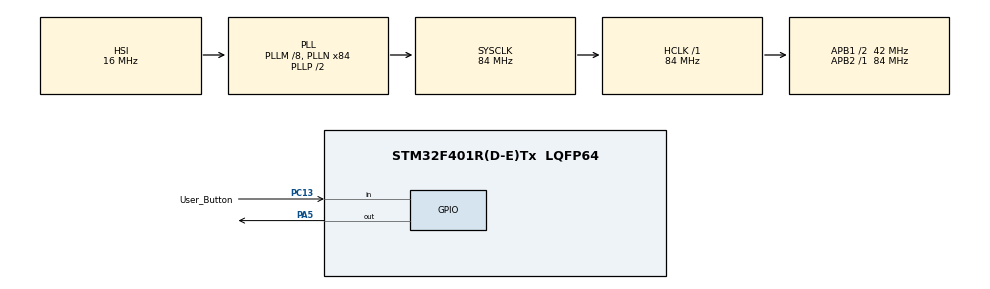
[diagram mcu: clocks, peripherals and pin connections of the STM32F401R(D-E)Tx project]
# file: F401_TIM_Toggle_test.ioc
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Mcu.Family=STM32F4
Mcu.Name=STM32F401R(D-E)Tx
Mcu.Package=LQFP64
NVIC.PriorityGroup=NVIC_PRIORITYGROUP_4
NVIC.TIM1_UP_TIM10_IRQn=true\:0\:0\:false\:false\:true\:true\:true
PA13.Mode=Serial_Wire
PA13.Signal=SYS_JTMS-SWDIO
PA14.Mode=Serial_Wire
PA14.Signal=SYS_JTCK-SWCLK
PA5.Signal=GPIO_Output
PC13-ANTI_TAMP.GPIO_Label=User_Button
PC13-ANTI_TAMP.Signal=GPIO_Input
ProjectManager.HeapSize=0x200
ProjectManager.StackSize=0x400
ProjectManager.TargetToolchain=STM32CubeIDE
RCC.48MHZClocksFreq_Value=42000000
RCC.AHBFreq_Value=84000000
RCC.APB1CLKDivider=RCC_HCLK_DIV2
RCC.APB1Freq_Value=42000000
RCC.APB1TimFreq_Value=84000000
RCC.APB2Freq_Value=84000000
RCC.APB2TimFreq_Value=84000000
RCC.CortexFreq_Value=84000000
RCC.HCLKFreq_Value=84000000
RCC.HSE_VALUE=25000000
RCC.HSI_VALUE=16000000
RCC.LSE_VALUE=32768
RCC.PLLM=8
RCC.PLLN=84
RCC.SYSCLKFreq_VALUE=84000000
RCC.SYSCLKSource=RCC_SYSCLKSOURCE_PLLCLK
RCC.VCOOutputFreq_Value=168000000
TIM1.Period=100-1
TIM1.Prescaler=84-1
VP_TIM1_VS_ClockSourceINT.Mode=Internal
board=custom

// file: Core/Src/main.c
/* USER CODE BEGIN Header */
/**
  ******************************************************************************
  * @file           : main.c
  * @brief          : Main program body
  ******************************************************************************
  * @attention
  *
  * <h2><center>&copy; Copyright (c) 2021 STMicroelectronics.
  * All rights reserved.</center></h2>
  *
  * This software component is licensed by ST under BSD 3-Clause license,
  * the "License"; You may not use this file except in compliance with the
  * License. You may obtain a copy of the License at:
  *                        opensource.org/licenses/BSD-3-Clause
  *
  ******************************************************************************
  */
/* USER CODE END Header */
#include "main.h"

/* USER CODE BEGIN PTD */
#define HIGH 	1
#define LOW		0
#define FIRST_PUSH	1
#define OLD_PUSH 	0
#define BUTTON_PUSH		0
#define BUTTON_RELEASE	1
#define MIN_COUNT 1
/* USER CODE END PTD */

TIM_HandleTypeDef htim1;

void SystemClock_Config(void);
static void MX_GPIO_Init(void);
static void MX_TIM1_Init(void);

/* USER CODE BEGIN 0 */
unsigned char g_TIM1_Status = 0;
/* USER CODE END 0 */

int main(void)
{
  /* USER CODE BEGIN 1 */
#define LED_TOGLE	0
#define LED_OFF		1

char led_status=LED_OFF;
char button_count=0;
char old_button=0;
  /* USER CODE END 1 */

  /* MCU Configuration--------------------------------------------------------*/

  /* Reset of all peripherals, Initializes the Flash interface and the Systick. */
  HAL_Init();

  /* Configure the system clock */
  SystemClock_Config();

  /* Initialize all configured peripherals */
  MX_GPIO_Init();
  MX_TIM1_Init();
  /* USER CODE BEGIN 2 */
  HAL_TIM_Base_Start_IT(&htim1);
  /* USER CODE END 2 */

  /* Infinite loop */
  while (1)
  {

    /* USER CODE BEGIN 3 */
	  /////////////////////   Button Input
	 	  if((HAL_GPIO_ReadPin(GPIOC, User_Button_Pin) == BUTTON_PUSH)&&(old_button==0))
	 	  {
	 		  button_count++;
	 		  if(button_count > MIN_COUNT)
	 		  {
	 			  if(led_status==LED_OFF)
	 				  led_status=LED_TOGLE;
	 			  else
	 				  led_status=LED_OFF;

	 			  old_button=1;
	 		  }
	 	  }
	 	  else if(HAL_GPIO_ReadPin(GPIOC, User_Button_Pin) == BUTTON_RELEASE)
	 	  {
	 		  old_button=0;
	 		  button_count=0;
	 	  }

	 	  /////////////////////   LED CTRL
	 	  if((led_status==LED_TOGLE)&&(g_TIM1_Status))
	 	  {
	 		  g_TIM1_Status = LOW;																	// g_TIM1_status is 0
	 		  HAL_GPIO_TogglePin(GPIOA,GPIO_PIN_5);
	 	  }
	 	  else if(led_status==LED_OFF)
	 	  {
	 		  HAL_GPIO_WritePin(GPIOA, GPIO_PIN_5, RESET);
	 	  }
  }
  /* USER CODE END 3 */
}

void SystemClock_Config(void)
{
  RCC_OscInitTypeDef RCC_OscInitStruct = {0};
  RCC_ClkInitTypeDef RCC_ClkInitStruct = {0};

  /** Configure the main internal regulator output voltage
  */
  __HAL_RCC_PWR_CLK_ENABLE();
  __HAL_PWR_VOLTAGESCALING_CONFIG(PWR_REGULATOR_VOLTAGE_SCALE2);
  /** Initializes the RCC Oscillators according to the specified parameters
  * in the RCC_OscInitTypeDef structure.
  */
  RCC_OscInitStruct.OscillatorType = RCC_OSCILLATORTYPE_HSI;
  RCC_OscInitStruct.HSIState = RCC_HSI_ON;
  RCC_OscInitStruct.HSICalibrationValue = RCC_HSICALIBRATION_DEFAULT;
  RCC_OscInitStruct.PLL.PLLState = RCC_PLL_ON;
  RCC_OscInitStruct.PLL.PLLSource = RCC_PLLSOURCE_HSI;
  RCC_OscInitStruct.PLL.PLLM = 8;
  RCC_OscInitStruct.PLL.PLLN = 84;
  RCC_OscInitStruct.PLL.PLLP = RCC_PLLP_DIV2;
  RCC_OscInitStruct.PLL.PLLQ = 4;
  if (HAL_RCC_OscConfig(&RCC_OscInitStruct) != HAL_OK)
  {
    Error_Handler();
  }
  /** Initializes the CPU, AHB and APB buses clocks
  */
  RCC_ClkInitStruct.ClockType = RCC_CLOCKTYPE_HCLK|RCC_CLOCKTYPE_SYSCLK
                              |RCC_CLOCKTYPE_PCLK1|RCC_CLOCKTYPE_PCLK2;
  RCC_ClkInitStruct.SYSCLKSource = RCC_SYSCLKSOURCE_PLLCLK;
  RCC_ClkInitStruct.AHBCLKDivider = RCC_SYSCLK_DIV1;
  RCC_ClkInitStruct.APB1CLKDivider = RCC_HCLK_DIV2;
  RCC_ClkInitStruct.APB2CLKDivider = RCC_HCLK_DIV1;

  if (HAL_RCC_ClockConfig(&RCC_ClkInitStruct, FLASH_LATENCY_2) != HAL_OK)
  {
    Error_Handler();
  }
}

static void MX_TIM1_Init(void)
{

  TIM_ClockConfigTypeDef sClockSourceConfig = {0};
  TIM_MasterConfigTypeDef sMasterConfig = {0};

  htim1.Instance = TIM1;
  htim1.Init.Prescaler = 84-1;
  htim1.Init.CounterMode = TIM_COUNTERMODE_UP;
  htim1.Init.Period = 100-1;
  htim1.Init.ClockDivision = TIM_CLOCKDIVISION_DIV1;
  htim1.Init.RepetitionCounter = 0;
  htim1.Init.AutoReloadPreload = TIM_AUTORELOAD_PRELOAD_DISABLE;
  if (HAL_TIM_Base_Init(&htim1) != HAL_OK)
  {
    Error_Handler();
  }
  sClockSourceConfig.ClockSource = TIM_CLOCKSOURCE_INTERNAL;
  if (HAL_TIM_ConfigClockSource(&htim1, &sClockSourceConfig) != HAL_OK)
  {
    Error_Handler();
  }
  sMasterConfig.MasterOutputTrigger = TIM_TRGO_RESET;
  sMasterConfig.MasterSlaveMode = TIM_MASTERSLAVEMODE_DISABLE;
  if (HAL_TIMEx_MasterConfigSynchronization(&htim1, &sMasterConfig) != HAL_OK)
  {
    Error_Handler();
  }

}

static void MX_GPIO_Init(void)
{
  GPIO_InitTypeDef GPIO_InitStruct = {0};

  /* GPIO Ports Clock Enable */
  __HAL_RCC_GPIOC_CLK_ENABLE();
  __HAL_RCC_GPIOA_CLK_ENABLE();

  /*Configure GPIO pin Output Level */
  HAL_GPIO_WritePin(GPIOA, GPIO_PIN_5, GPIO_PIN_RESET);

  /*Configure GPIO pin : User_Button_Pin */
  GPIO_InitStruct.Pin = User_Button_Pin;
  GPIO_InitStruct.Mode = GPIO_MODE_INPUT;
  GPIO_InitStruct.Pull = GPIO_NOPULL;
  HAL_GPIO_Init(User_Button_GPIO_Port, &GPIO_InitStruct);

  /*Configure GPIO pin : PA5 */
  GPIO_InitStruct.Pin = GPIO_PIN_5;
  GPIO_InitStruct.Mode = GPIO_MODE_OUTPUT_PP;
  GPIO_InitStruct.Pull = GPIO_NOPULL;
  GPIO_InitStruct.Speed = GPIO_SPEED_FREQ_LOW;
  HAL_GPIO_Init(GPIOA, &GPIO_InitStruct);

}

/* USER CODE BEGIN 4 */
void HAL_TIM_PeriodElapsedCallback(TIM_HandleTypeDef *htim)
{
	g_TIM1_Status = HIGH;																// TIM status HIGH
}
/* USER CODE END 4 */

void Error_Handler(void)
{
  __disable_irq();
  while (1)
  {
  }
}

/************************ (C) COPYRIGHT STMicroelectronics *****END OF FILE****/
